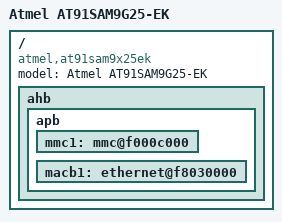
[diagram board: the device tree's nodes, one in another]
/*
 * at91sam9x25ek.dts - Device Tree file for AT91SAM9X25-EK board
 *
 *  Copyright (C) 2012 Atmel,
 *                2012 Nicolas Ferre <nicolas.ferre@atmel.com>
 *
 * Licensed under GPLv2 or later.
 */
/dts-v1/;
/include/ "at91sam9x25.dtsi"
/include/ "at91sam9x5ek.dtsi"

/ {
	model = "Atmel AT91SAM9G25-EK";
	compatible = "atmel,at91sam9x25ek", "atmel,at91sam9x5ek", "atmel,at91sam9x5", "atmel,at91sam9";

	ahb {
		apb {
			mmc1: mmc@f000c000 {
				status = "okay";
			};

			macb1: ethernet@f8030000 {
				status = "okay";
			};
		};
	};
};
